# MCXC444 register map
Vendor: NXP Semiconductors; Series: MCX; File version: 1.6
CPU: CM0PLUS r0p0, little endian, no MPU, no FPU, VTOR, 2 interrupt priority bits
Registers are 32-bit, read-write, reset 0x0 unless marked. A register's access mark holds for its fields unless they carry their own. Offsets are from the block's base; [hi:lo] are bit positions; {n}, {i} and the like mark numbered series.

## ADC0 — Analog-to-Digital Converter
Base 0x4003B000; register names take the prefix ADC0_
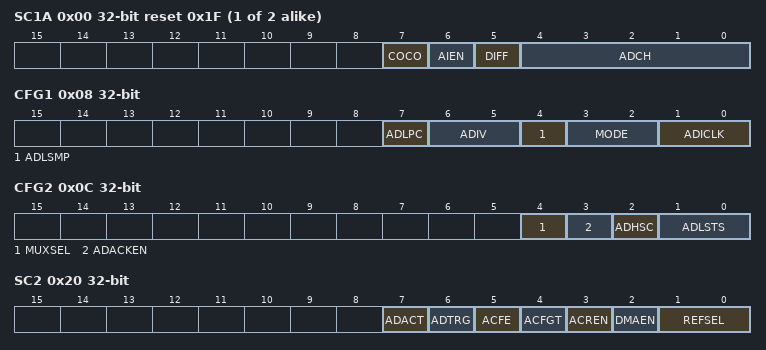
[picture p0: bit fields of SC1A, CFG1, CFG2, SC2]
0x00 SC1{x} (x=A,B; step 0x4) reset 0x1F — ADC Status and Control Registers 1
  [7] COCO ro — Conversion Complete Flag
    0=b0 (Conversion is not completed.); 1=b1 (Conversion is completed.)
  [6] AIEN — Interrupt Enable
    0=b0 (Conversion complete interrupt is disabled.); 1=b1 (Conversion complete interrupt is enabled.)
  [5] DIFF — Differential Mode Enable
    0=b0 (Single-ended conversions and input channels are selected.); 1=b1 (Differential conversions and input channels are selected.)
  [4:0] ADCH — Input channel select
    0=b00000 (When DIFF=0, DADP0 is selected as input; when DIFF=1, DAD0 is selected as input.); 1=b00001 (When DIFF=0, DADP1 is selected as input; when DIFF=1, DAD1 is selected as input.); 2=b00010 (When DIFF=0, DADP2 is selected as input; when DIFF=1, DAD2 is selected as input.); 3=b00011 (When DIFF=0, DADP3 is selected as input; when DIFF=1, DAD3 is selected as input.); 4=b00100 (When DIFF=0, AD4 is selected as input; when DIFF=1, it is reserved.); 5=b00101 (When DIFF=0, AD5 is selected as input; when DIFF=1, it is reserved.); 6=b00110 (When DIFF=0, AD6 is selected as input; when DIFF=1, it is reserved.); 7=b00111 (When DIFF=0, AD7 is selected as input; when DIFF=1, it is reserved.); 8=b01000 (When DIFF=0, AD8 is selected as input; when DIFF=1, it is reserved.); 9=b01001 (When DIFF=0, AD9 is selected as input; when DIFF=1, it is reserved.); 10=b01010 (When DIFF=0, AD10 is selected as input; when DIFF=1, it is reserved.); 11=b01011 (When DIFF=0, AD11 is selected as input; when DIFF=1, it is reserved.); 12=b01100 (When DIFF=0, AD12 is selected as input; when DIFF=1, it is reserved.); 13=b01101 (When DIFF=0, AD13 is selected as input; when DIFF=1, it is reserved.); 14=b01110 (When DIFF=0, AD14 is selected as input; when DIFF=1, it is reserved.); 15=b01111 (When DIFF=0, AD15 is selected as input; when DIFF=1, it is reserved.); 16=b10000 (When DIFF=0, AD16 is selected as input; when DIFF=1, it is reserved.); 17=b10001 (When DIFF=0, AD17 is selected as input; when DIFF=1, it is reserved.); 18=b10010 (When DIFF=0, AD18 is selected as input; when DIFF=1, it is reserved.); 19=b10011 (When DIFF=0, AD19 is selected as input; when DIFF=1, it is reserved.); 20=b10100 (When DIFF=0, AD20 is selected as input; when DIFF=1, it is reserved.); 21=b10101 (When DIFF=0, AD21 is selected as input; when DIFF=1, it is reserved.); 22=b10110 (When DIFF=0, AD22 is selected as input; when DIFF=1, it is reserved.); 23=b10111 (When DIFF=0, AD23 is selected as input; when DIFF=1, it is reserved.); 26=b11010 (When DIFF=0, Temp Sensor (single-ended) is selected as input; when DIFF=1, Temp Sensor (differential) is selected as input.); 27=b11011 (When DIFF=0, Bandgap (single-ended) is selected as input; when DIFF=1, Bandgap (differential) is selected as input.); 29=b11101 (When DIFF=0,VREFSH is selected as input; when DIFF=1, -VREFSH (differential) is selected as input. Voltage reference selected is determined by SC2[REFSEL].); 30=b11110 (When DIFF=0,VREFSL is selected as input; when DIFF=1, it is reserved. Voltage reference selected is determined by SC2[REFSEL].); 31=b11111 (Module is disabled.)
0x08 CFG1 — ADC Configuration Register 1
  [7] ADLPC — Low-Power Configuration
    0=b0 (Normal power configuration.); 1=b1 (Low-power configuration. The power is reduced at the expense of maximum clock speed.)
  [6:5] ADIV — Clock Divide Select
    0=b00 (The divide ratio is 1 and the clock rate is input clock.); 1=b01 (The divide ratio is 2 and the clock rate is (input clock)/2.); 2=b10 (The divide ratio is 4 and the clock rate is (input clock)/4.); 3=b11 (The divide ratio is 8 and the clock rate is (input clock)/8.)
  [4] ADLSMP — Sample Time Configuration
    0=b0 (Short sample time.); 1=b1 (Long sample time.)
  [3:2] MODE — Conversion mode selection
    0=b00 (When DIFF=0:It is single-ended 8-bit conversion; when DIFF=1, it is differential 9-bit conversion with 2's complement output.); 1=b01 (When DIFF=0:It is single-ended 12-bit conversion ; when DIFF=1, it is differential 13-bit conversion with 2's complement output.); 2=b10 (When DIFF=0:It is single-ended 10-bit conversion. ; when DIFF=1, it is differential 11-bit conversion with 2's complement output); 3=b11 (When DIFF=0:It is single-ended 16-bit conversion..; when DIFF=1, it is differential 16-bit conversion with 2's complement output)
  [1:0] ADICLK — Input Clock Select
    0=b00 (Bus clock); 1=b01 (Bus clock divided by 2(BUSCLK/DIV2)); 2=b10 (Alternate clock (ALTCLK)); 3=b11 (Asynchronous clock (ADACK))
0x0C CFG2 — ADC Configuration Register 2
  [4] MUXSEL — ADC Mux Select
    0=b0 (ADxxa channels are selected.); 1=b1 (ADxxb channels are selected.)
  [3] ADACKEN — Asynchronous Clock Output Enable
    0=b0 (Asynchronous clock output disabled; Asynchronous clock is enabled only if selected by ADICLK and a conversion is active.); 1=b1 (Asynchronous clock and clock output is enabled regardless of the state of the ADC.)
  [2] ADHSC — High-Speed Configuration
    0=b0 (Normal conversion sequence selected.); 1=b1 (High-speed conversion sequence selected with 2 additional ADCK cycles to total conversion time.)
  [1:0] ADLSTS — Long Sample Time Select
    0=b00 (Default longest sample time; 20 extra ADCK cycles; 24 ADCK cycles total.); 1=b01 (12 extra ADCK cycles; 16 ADCK cycles total sample time.); 2=b10 (6 extra ADCK cycles; 10 ADCK cycles total sample time.); 3=b11 (2 extra ADCK cycles; 6 ADCK cycles total sample time.)
0x10 R{x} (x=A,B; step 0x4) ro — ADC Data Result Register
  [15:0] D — Data result
{0x14+4i} CV{i} (i=1..2) — Compare Value Registers
  [15:0] CV — Compare Value.
0x20 SC2 — Status and Control Register 2
  [7] ADACT ro — Conversion Active
    0=b0 (Conversion not in progress.); 1=b1 (Conversion in progress.)
  [6] ADTRG — Conversion Trigger Select
    0=b0 (Software trigger selected.); 1=b1 (Hardware trigger selected.)
  [5] ACFE — Compare Function Enable
    0=b0 (Compare function disabled.); 1=b1 (Compare function enabled.)
  [4] ACFGT — Compare Function Greater Than Enable
    0=b0 (Configures less than threshold, outside range not inclusive and inside range not inclusive; functionality based on the values placed in CV1 and CV2.); 1=b1 (Configures greater than or equal to threshold, outside and inside ranges inclusive; functionality based on the values placed in CV1 and CV2.)
  [3] ACREN — Compare Function Range Enable
    0=b0 (Range function disabled. Only CV1 is compared.); 1=b1 (Range function enabled. Both CV1 and CV2 are compared.)
  [2] DMAEN — DMA Enable
    0=b0 (DMA is disabled.); 1=b1 (DMA is enabled and will assert the ADC DMA request during an ADC conversion complete event noted when any of the SC1n[COCO] flags is asserted.)
  [1:0] REFSEL — Voltage Reference Selection
    0=b00 (Default voltage reference pin pair, that is, external pins VREFH and VREFL); 1=b01 (Alternate reference pair, that is, VALTH and VALTL . This pair may be additional external pins or internal sources depending on the MCU configuration. See the chip configuration information for details specific to this MCU)
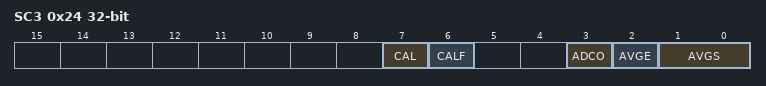
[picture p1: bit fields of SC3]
0x24 SC3 — Status and Control Register 3
  [7] CAL — Calibration
  [6] CALF — Calibration Failed Flag
    0=b0 (Calibration completed normally.); 1=b1 (Calibration failed. ADC accuracy specifications are not guaranteed.)
  [3] ADCO — Continuous Conversion Enable
    0=b0 (One conversion or one set of conversions if the hardware average function is enabled, that is, AVGE=1, after initiating a conversion.); 1=b1 (Continuous conversions or sets of conversions if the hardware average function is enabled, that is, AVGE=1, after initiating a conversion.)
  [2] AVGE — Hardware Average Enable
    0=b0 (Hardware average function disabled.); 1=b1 (Hardware average function enabled.)
  [1:0] AVGS — Hardware Average Select
    0=b00 (4 samples averaged.); 1=b01 (8 samples averaged.); 2=b10 (16 samples averaged.); 3=b11 (32 samples averaged.)
0x28 OFS reset 0x4 — ADC Offset Correction Register
  [15:0] OFS — Offset Error Correction Value
0x2C PG reset 0x8200 — ADC Plus-Side Gain Register
  [15:0] PG — Plus-Side Gain
0x30 MG reset 0x8200 — ADC Minus-Side Gain Register
  [15:0] MG — Minus-Side Gain
0x34 CLPD reset 0xA — ADC Plus-Side General Calibration Value Register
  [5:0] CLPD — Calibration Value
0x38 CLPS reset 0x20 — ADC Plus-Side General Calibration Value Register
  [5:0] CLPS — Calibration Value
0x3C CLP4 reset 0x200 — ADC Plus-Side General Calibration Value Register
  [9:0] CLP4 — Calibration Value
0x40 CLP3 reset 0x100 — ADC Plus-Side General Calibration Value Register
  [8:0] CLP3 — Calibration Value
0x44 CLP2 reset 0x80 — ADC Plus-Side General Calibration Value Register
  [7:0] CLP2 — Calibration Value
0x48 CLP1 reset 0x40 — ADC Plus-Side General Calibration Value Register
  [6:0] CLP1 — Calibration Value
0x4C CLP0 reset 0x20 — ADC Plus-Side General Calibration Value Register
  [5:0] CLP0 — Calibration Value
0x54 CLMD reset 0xA — ADC Minus-Side General Calibration Value Register
  [5:0] CLMD — Calibration Value
0x58 CLMS reset 0x20 — ADC Minus-Side General Calibration Value Register
  [5:0] CLMS — Calibration Value
0x5C CLM4 reset 0x200 — ADC Minus-Side General Calibration Value Register
  [9:0] CLM4 — Calibration Value
0x60 CLM3 reset 0x100 — ADC Minus-Side General Calibration Value Register
  [8:0] CLM3 — Calibration Value
0x64 CLM2 reset 0x80 — ADC Minus-Side General Calibration Value Register
  [7:0] CLM2 — Calibration Value
0x68 CLM1 reset 0x40 — ADC Minus-Side General Calibration Value Register
  [6:0] CLM1 — Calibration Value
0x6C CLM0 reset 0x20 — ADC Minus-Side General Calibration Value Register
  [5:0] CLM0 — Calibration Value
